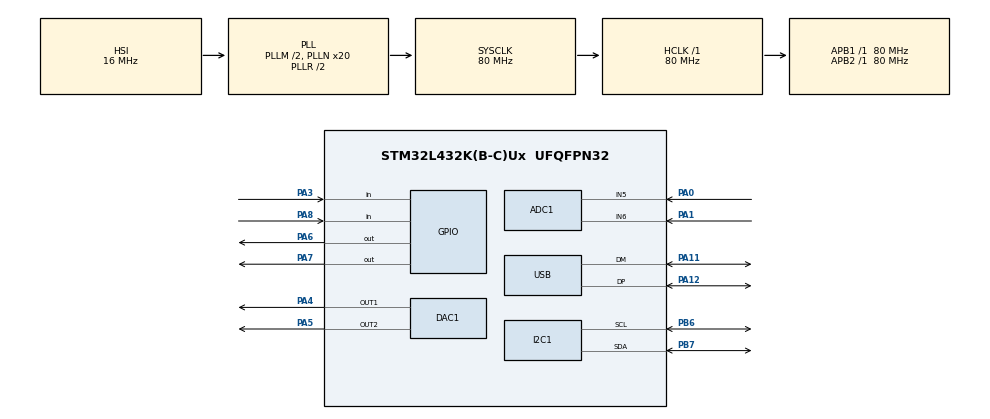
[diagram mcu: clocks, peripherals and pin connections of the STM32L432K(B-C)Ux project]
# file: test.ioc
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ADC1.AutoInjectedConv=DISABLE
ADC1.Channel-31\#ChannelRegularConversion=ADC_CHANNEL_5
ADC1.DMAContinuousRequests=ENABLE
ADC1.ExternalTrigConv=ADC_EXTERNALTRIG_T2_TRGO
ADC1.InjectedDiscontinuousConvMode=DISABLE
ADC1.NbrOfConversionFlag=1
ADC1.OffsetNumber-31\#ChannelRegularConversion=ADC_OFFSET_NONE
ADC1.Rank-31\#ChannelRegularConversion=1
ADC1.SamplingTime-31\#ChannelRegularConversion=ADC_SAMPLETIME_2CYCLES_5
ADC1.SingleDiff-31\#ChannelRegularConversion=ADC_DIFFERENTIAL_ENDED
ADC1.master=1
DAC1.DAC_Channel-DAC_OUT1=DAC_CHANNEL_1
DAC1.DAC_Channel-DAC_OUT2=DAC_CHANNEL_2
DAC1.DAC_Trigger-DAC_OUT2=DAC_TRIGGER_T6_TRGO
DAC1.WaveGeneration-DAC_OUT1=DISABLE
DAC1.WaveGeneration-DAC_OUT2=DISABLE
Dma.ADC1.1.Direction=DMA_PERIPH_TO_MEMORY
Dma.ADC1.1.Instance=DMA1_Channel1
Dma.ADC1.1.MemDataAlignment=DMA_MDATAALIGN_HALFWORD
Dma.ADC1.1.MemInc=DMA_MINC_ENABLE
Dma.ADC1.1.Mode=DMA_CIRCULAR
Dma.ADC1.1.PeriphDataAlignment=DMA_PDATAALIGN_HALFWORD
Dma.ADC1.1.PeriphInc=DMA_PINC_DISABLE
Dma.ADC1.1.Priority=DMA_PRIORITY_LOW
Dma.DAC_CH2.0.Direction=DMA_MEMORY_TO_PERIPH
Dma.DAC_CH2.0.Instance=DMA1_Channel4
Dma.DAC_CH2.0.MemDataAlignment=DMA_MDATAALIGN_HALFWORD
Dma.DAC_CH2.0.MemInc=DMA_MINC_ENABLE
Dma.DAC_CH2.0.Mode=DMA_CIRCULAR
Dma.DAC_CH2.0.PeriphDataAlignment=DMA_PDATAALIGN_HALFWORD
Dma.DAC_CH2.0.PeriphInc=DMA_PINC_DISABLE
Dma.DAC_CH2.0.Priority=DMA_PRIORITY_LOW
Dma.Request0=DAC_CH2
Dma.Request1=ADC1
I2C1.OwnAddress2Masks=I2C_OA2_NOMASK
Mcu.Family=STM32L4
Mcu.Name=STM32L432K(B-C)Ux
Mcu.Package=UFQFPN32
NVIC.DMA1_Channel1_IRQn=true\:0\:0\:false\:false\:true
NVIC.DMA1_Channel4_IRQn=true\:0\:0\:false\:false\:true
NVIC.PriorityGroup=NVIC_PRIORITYGROUP_4
NVIC.USB_IRQn=true\:0\:0\:false\:false\:true
PA0-CK_IN.Signal=ADCx_IN5
PA1.Signal=ADCx_IN6
PA11.Mode=Device
PA11.Signal=USB_DM
PA12.Mode=Device
PA12.Signal=USB_DP
PA13\ (JTMS-SWDIO).Signal=SYS_JTMS-SWDIO
PA14\ (JTCK-SWCLK).Signal=SYS_JTCK-SWCLK
PA3.GPIO_Mode=GPIO_MODE_INPUT
PA3.GPIO_PuPd=GPIO_NOPULL
PA3.Signal=GPIO_Input
PA4.GPIO_Mode=GPIO_MODE_ANALOG
PA4.GPIO_PuPd=GPIO_NOPULL
PA4.Signal=COMP_DAC11_group
PA5.GPIO_Mode=GPIO_MODE_ANALOG
PA5.GPIO_PuPd=GPIO_NOPULL
PA5.Signal=COMP_DAC12_group
PA6.GPIO_ModeDefaultOutputPP=GPIO_MODE_OUTPUT_PP
PA6.GPIO_PuPd=GPIO_NOPULL
PA6.GPIO_Speed=GPIO_SPEED_FREQ_LOW
PA6.PinState=GPIO_PIN_RESET
PA6.Signal=GPIO_Output
PA7.GPIO_ModeDefaultOutputPP=GPIO_MODE_OUTPUT_PP
PA7.GPIO_PuPd=GPIO_NOPULL
PA7.GPIO_Speed=GPIO_SPEED_FREQ_LOW
PA7.PinState=GPIO_PIN_RESET
PA7.Signal=GPIO_Output
PA8.GPIO_Mode=GPIO_MODE_INPUT
PA8.GPIO_PuPd=GPIO_NOPULL
PA8.Signal=GPIO_Input
PB6.GPIO_FM6=__NULL
PB6.GPIO_Mode=GPIO_MODE_AF_OD
PB6.GPIO_PuPdOD=GPIO_PULLUP
PB6.GPIO_Speed=GPIO_SPEED_FREQ_VERY_HIGH
PB6.Mode=I2C
PB6.Signal=I2C1_SCL
PB7.GPIO_FM7=__NULL
PB7.GPIO_Mode=GPIO_MODE_AF_OD
PB7.GPIO_PuPdOD=GPIO_PULLUP
PB7.GPIO_Speed=GPIO_SPEED_FREQ_VERY_HIGH
PB7.Mode=I2C
PB7.Signal=I2C1_SDA
RCC.ADCCLockSelection=RCC_ADCCLKSOURCE_SYSCLK
RCC.ADCFreq_Value=80000000
RCC.AHBCLKDivider=RCC_SYSCLK_DIV1
RCC.AHBFreq_Value=80000000
RCC.APB1Freq_Value=80000000
RCC.APB1TimFreq_Value=80000000
RCC.APB2Freq_Value=80000000
RCC.APB2TimFreq_Value=80000000
RCC.CK48CLockSelection=RCC_USBCLKSOURCE_HSI48
RCC.ClockTypeHCLK=RCC_CLOCKTYPE_HCLK
RCC.ClockTypePCLK1=RCC_CLOCKTYPE_PCLK1
RCC.ClockTypePCLK2=RCC_CLOCKTYPE_PCLK2
RCC.ClockTypeSysClk=RCC_CLOCKTYPE_SYSCLK
RCC.CortexFreq_Value=80000000
RCC.EnableCSSLSE=false
RCC.EnbaleCSS=false
RCC.HCLKFreq_Value=80000000
RCC.HSE_VALUE=8000000
RCC.HSI48_VALUE=48000000
RCC.HSI_VALUE=16000000
RCC.I2C1CLockSelection=RCC_I2C1CLKSOURCE_SYSCLK
RCC.LSE_VALUE=32768
RCC.MSIClockRange=RCC_MSIRANGE_9
RCC.MSI_VALUE=24000000
RCC.PLLM=2
RCC.PLLN=20
RCC.PLLR=RCC_PLLR_DIV2
RCC.PLLSAI1N=20
RCC.PLLSAI1Q=RCC_PLLQ_DIV2
RCC.PLLSAI1R=RCC_PLLR_DIV2
RCC.PLLSourceVirtual=RCC_PLLSOURCE_HSI
RCC.SYSCLKFreq_VALUE=80000000
RCC.SYSCLKSource=RCC_SYSCLKSOURCE_PLLCLK
RCC.USBFreq_Value=48000000
RCC.VCOOutputFreq_Value=160000000
SH.ADCx_IN5.0=ADC1_IN5,IN5-Differential
SH.ADCx_IN6.0=ADC1_IN6,IN5-Differential
SH.COMP_DAC11_group.0=DAC1_OUT1,DAC_OUT1
SH.COMP_DAC12_group.0=DAC1_OUT2,DAC_OUT2
TIM2.Period=800
TIM2.TIM_MasterOutputTrigger=TIM_TRGO_UPDATE
TIM6.Period=800
TIM6.TIM_MasterSlaveMode=TIM_MASTERSLAVEMODE_DISABLE
USB_DEVICE.CLASS_NAME_FS=CDC
USB_DEVICE.USBD_HandleTypeDef_FS=hUsbDevice_USB_FS
USB_DEVICE.VirtualMode=Cdc
USB_DEVICE.VirtualModeFS=Cdc_FS
VP_TIM2_VS_ClockSourceINT.Mode=Internal
VP_TIM6_VS_ClockSourceINT.Mode=Enable_Timer
VP_USB_DEVICE_VS_USB_DEVICE_CDC_FS.Mode=CDC_FS

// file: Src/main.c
/**
  ******************************************************************************
  * File Name          : main.c
  * Description        : Main program body
  ******************************************************************************
  *
  * Copyright (c) 2017 STMicroelectronics International N.V.
  * All rights reserved.
  *
  * Redistribution and use in source and binary forms, with or without
  * modification, are permitted, provided that the following conditions are met:
  *
  * 1. Redistribution of source code must retain the above copyright notice,
  *    this list of conditions and the following disclaimer.
  * 2. Redistributions in binary form must reproduce the above copyright notice,
  *    this list of conditions and the following disclaimer in the documentation
  *    and/or other materials provided with the distribution.
  * 3. Neither the name of STMicroelectronics nor the names of other
  *    contributors to this software may be used to endorse or promote products
  *    derived from this software without specific written permission.
  * 4. This software, including modifications and/or derivative works of this
  *    software, must execute solely and exclusively on microcontroller or
  *    microprocessor devices manufactured by or for STMicroelectronics.
  * 5. Redistribution and use of this software other than as permitted under
  *    this license is void and will automatically terminate your rights under
  *    this license.
  *
  * THIS SOFTWARE IS PROVIDED BY STMICROELECTRONICS AND CONTRIBUTORS "AS IS"
  * AND ANY EXPRESS, IMPLIED OR STATUTORY WARRANTIES, INCLUDING, BUT NOT
  * LIMITED TO, THE IMPLIED WARRANTIES OF MERCHANTABILITY, FITNESS FOR A
  * PARTICULAR PURPOSE AND NON-INFRINGEMENT OF THIRD PARTY INTELLECTUAL PROPERTY
  * RIGHTS ARE DISCLAIMED TO THE FULLEST EXTENT PERMITTED BY LAW. IN NO EVENT
  * SHALL STMICROELECTRONICS OR CONTRIBUTORS BE LIABLE FOR ANY DIRECT, INDIRECT,
  * INCIDENTAL, SPECIAL, EXEMPLARY, OR CONSEQUENTIAL DAMAGES (INCLUDING, BUT NOT
  * LIMITED TO, PROCUREMENT OF SUBSTITUTE GOODS OR SERVICES; LOSS OF USE, DATA,
  * OR PROFITS; OR BUSINESS INTERRUPTION) HOWEVER CAUSED AND ON ANY THEORY OF
  * LIABILITY, WHETHER IN CONTRACT, STRICT LIABILITY, OR TORT (INCLUDING
  * NEGLIGENCE OR OTHERWISE) ARISING IN ANY WAY OUT OF THE USE OF THIS SOFTWARE,
  * EVEN IF ADVISED OF THE POSSIBILITY OF SUCH DAMAGE.
  *
  ******************************************************************************
  */
#include "main.h"
#include "stm32l4xx_hal.h"
#include "usb_device.h"
#include "dac_values.h"
#include "stm32l4xx_it.h"

ADC_HandleTypeDef hadc1;
DMA_HandleTypeDef hdma_adc1;

DAC_HandleTypeDef hdac1;
DMA_HandleTypeDef hdma_dac_ch2;

I2C_HandleTypeDef hi2c1;

TIM_HandleTypeDef htim2;
TIM_HandleTypeDef htim6;

/* USER CODE BEGIN PV */
/* Private variables ---------------------------------------------------------*/

/* USER CODE END PV */

void SystemClock_Config(void);
void Error_Handler(void);
static void MX_GPIO_Init(void);
static void MX_DMA_Init(void);
static void MX_DAC1_Init(void);
static void MX_I2C1_Init(void);
static void MX_TIM2_Init(void);
static void MX_ADC1_Init(void);
static void MX_TIM6_Init(void);
volatile int x = 0;
volatile int y = 0;
volatile uint16_t dac_buffer[2048] = DAC_BUFF;
volatile int z = 0;
volatile int q = 0;
int counter = 0;

/* USER CODE BEGIN PFP */
/* Private function prototypes -----------------------------------------------*/

/* USER CODE END PFP */

int main(void)
{

  /* MCU Configuration----------------------------------------------------------*/

  /* Reset of all peripherals, Initializes the Flash interface and the Systick. */
  HAL_Init();

  /* Configure the system clock */
  SystemClock_Config();

  /* Initialize all configured peripherals */
  MX_GPIO_Init();
  MX_DMA_Init();
  MX_DAC1_Init();
  MX_I2C1_Init();
  MX_USB_DEVICE_Init();
  MX_TIM2_Init();
  MX_ADC1_Init();
  MX_TIM6_Init();

  /* Infinite loop */
  /* USER CODE BEGIN WHILE */

  //initialize DAC buffer
  //set up ADC and DAC DMA's
  HAL_TIM_Base_Start(&htim6);
  HAL_TIM_Base_Start(&htim2);

  HAL_GPIO_WritePin(GPIOB, GPIO_PIN_5, GPIO_PIN_SET);

  //wait for the timer to reach zero, to syncronize DMA's
  MX_USB_DEVICE_Init();
  while ((&htim6)->Instance->CNT != 0){
    //wait
  }
  HAL_DAC_Start_DMA(&hdac1, DAC_CHANNEL_2, dac_buffer, 2048, DAC_ALIGN_12B_R);
  HAL_ADC_Start_DMA(&hadc1, adc_buffer, 2048);

  //set AGC DAC
  HAL_DAC_Start(&hdac1, DAC_CHANNEL_1);
  HAL_DAC_SetValue(&hdac1, DAC_CHANNEL_1, DAC_ALIGN_12B_R, 300);
  HAL_DAC_Start(&hdac1, DAC_CHANNEL_1);

  while (1)
  {
  /* USER CODE END WHILE */
y = (&htim6)->Instance->CNT;
x++;

  }

}

/** System Clock Configuration
*/
void SystemClock_Config(void)
{

  RCC_OscInitTypeDef RCC_OscInitStruct;
  RCC_ClkInitTypeDef RCC_ClkInitStruct;
  RCC_PeriphCLKInitTypeDef PeriphClkInit;

    /**Initializes the CPU, AHB and APB busses clocks
    */
  RCC_OscInitStruct.OscillatorType = RCC_OSCILLATORTYPE_HSI48|RCC_OSCILLATORTYPE_HSI;
  RCC_OscInitStruct.HSIState = RCC_HSI_ON;
  RCC_OscInitStruct.HSI48State = RCC_HSI48_ON;
  RCC_OscInitStruct.HSICalibrationValue = 16;
  RCC_OscInitStruct.PLL.PLLState = RCC_PLL_ON;
  RCC_OscInitStruct.PLL.PLLSource = RCC_PLLSOURCE_HSI;
  RCC_OscInitStruct.PLL.PLLM = 2;
  RCC_OscInitStruct.PLL.PLLN = 20;
  RCC_OscInitStruct.PLL.PLLP = RCC_PLLP_DIV7;
  RCC_OscInitStruct.PLL.PLLQ = RCC_PLLQ_DIV2;
  RCC_OscInitStruct.PLL.PLLR = RCC_PLLR_DIV2;
  if (HAL_RCC_OscConfig(&RCC_OscInitStruct) != HAL_OK)
  {
    Error_Handler();
  }

    /**Initializes the CPU, AHB and APB busses clocks
    */
  RCC_ClkInitStruct.ClockType = RCC_CLOCKTYPE_HCLK|RCC_CLOCKTYPE_SYSCLK
                              |RCC_CLOCKTYPE_PCLK1|RCC_CLOCKTYPE_PCLK2;
  RCC_ClkInitStruct.SYSCLKSource = RCC_SYSCLKSOURCE_PLLCLK;
  RCC_ClkInitStruct.AHBCLKDivider = RCC_SYSCLK_DIV1;
  RCC_ClkInitStruct.APB1CLKDivider = RCC_HCLK_DIV1;
  RCC_ClkInitStruct.APB2CLKDivider = RCC_HCLK_DIV1;

  if (HAL_RCC_ClockConfig(&RCC_ClkInitStruct, FLASH_LATENCY_4) != HAL_OK)
  {
    Error_Handler();
  }

  PeriphClkInit.PeriphClockSelection = RCC_PERIPHCLK_I2C1|RCC_PERIPHCLK_USB
                              |RCC_PERIPHCLK_ADC;
  PeriphClkInit.I2c1ClockSelection = RCC_I2C1CLKSOURCE_SYSCLK;
  PeriphClkInit.AdcClockSelection = RCC_ADCCLKSOURCE_SYSCLK;
  PeriphClkInit.UsbClockSelection = RCC_USBCLKSOURCE_HSI48;
  if (HAL_RCCEx_PeriphCLKConfig(&PeriphClkInit) != HAL_OK)
  {
    Error_Handler();
  }

    /**Configure the main internal regulator output voltage
    */
  if (HAL_PWREx_ControlVoltageScaling(PWR_REGULATOR_VOLTAGE_SCALE1) != HAL_OK)
  {
    Error_Handler();
  }

    /**Configure the Systick interrupt time
    */
  HAL_SYSTICK_Config(HAL_RCC_GetHCLKFreq()/1000);

    /**Configure the Systick
    */
  HAL_SYSTICK_CLKSourceConfig(SYSTICK_CLKSOURCE_HCLK);

  /* SysTick_IRQn interrupt configuration */
  HAL_NVIC_SetPriority(SysTick_IRQn, 0, 0);
}

/* ADC1 init function */
static void MX_ADC1_Init(void)
{

  ADC_ChannelConfTypeDef sConfig;

    /**Common config
    */
  hadc1.Instance = ADC1;
  hadc1.Init.ClockPrescaler = ADC_CLOCK_ASYNC_DIV1;
  hadc1.Init.Resolution = ADC_RESOLUTION_12B;
  hadc1.Init.DataAlign = ADC_DATAALIGN_RIGHT;
  hadc1.Init.ScanConvMode = ADC_SCAN_DISABLE;
  hadc1.Init.EOCSelection = ADC_EOC_SINGLE_CONV;
  hadc1.Init.LowPowerAutoWait = DISABLE;
  hadc1.Init.ContinuousConvMode = DISABLE;
  hadc1.Init.NbrOfConversion = 1;
  hadc1.Init.DiscontinuousConvMode = DISABLE;
  hadc1.Init.NbrOfDiscConversion = 1;
  hadc1.Init.ExternalTrigConv = ADC_EXTERNALTRIG_T6_TRGO;
  hadc1.Init.ExternalTrigConvEdge = ADC_EXTERNALTRIGCONVEDGE_RISING;
  hadc1.Init.DMAContinuousRequests = ENABLE;
  hadc1.Init.Overrun = ADC_OVR_DATA_PRESERVED;
  hadc1.Init.OversamplingMode = DISABLE;
  if (HAL_ADC_Init(&hadc1) != HAL_OK)
  {
    Error_Handler();
  }

    /**Configure Regular Channel
    */
  sConfig.Channel = ADC_CHANNEL_5;
  sConfig.Rank = 1;
  sConfig.SamplingTime = ADC_SAMPLETIME_24CYCLES_5;
  sConfig.SingleDiff = ADC_DIFFERENTIAL_ENDED;
  sConfig.OffsetNumber = ADC_OFFSET_NONE;
  sConfig.Offset = 0;
  if (HAL_ADC_ConfigChannel(&hadc1, &sConfig) != HAL_OK)
  {
    Error_Handler();
  }

}

/* DAC1 init function */
static void MX_DAC1_Init(void)
{

  DAC_ChannelConfTypeDef sConfig;

    /**DAC Initialization
    */
  hdac1.Instance = DAC1;
  if (HAL_DAC_Init(&hdac1) != HAL_OK)
  {
    Error_Handler();
  }

    /**DAC channel OUT1 config
    */
  sConfig.DAC_SampleAndHold = DAC_SAMPLEANDHOLD_DISABLE;
  sConfig.DAC_Trigger = DAC_TRIGGER_NONE;
  sConfig.DAC_OutputBuffer = DAC_OUTPUTBUFFER_ENABLE;
  sConfig.DAC_ConnectOnChipPeripheral = DAC_CHIPCONNECT_DISABLE;
  sConfig.DAC_UserTrimming = DAC_TRIMMING_FACTORY;
  if (HAL_DAC_ConfigChannel(&hdac1, &sConfig, DAC_CHANNEL_1) != HAL_OK)
  {
    Error_Handler();
  }

    /**DAC channel OUT2 config
    */
  sConfig.DAC_Trigger = DAC_TRIGGER_T6_TRGO;
  sConfig.DAC_ConnectOnChipPeripheral = DAC_CHIPCONNECT_DISABLE;
  if (HAL_DAC_ConfigChannel(&hdac1, &sConfig, DAC_CHANNEL_2) != HAL_OK)
  {
    Error_Handler();
  }

}

/* I2C1 init function */
static void MX_I2C1_Init(void)
{

  hi2c1.Instance = I2C1;
  hi2c1.Init.Timing = 0x10909CEC;
  hi2c1.Init.OwnAddress1 = 0;
  hi2c1.Init.AddressingMode = I2C_ADDRESSINGMODE_7BIT;
  hi2c1.Init.DualAddressMode = I2C_DUALADDRESS_DISABLE;
  hi2c1.Init.OwnAddress2 = 0;
  hi2c1.Init.OwnAddress2Masks = I2C_OA2_NOMASK;
  hi2c1.Init.GeneralCallMode = I2C_GENERALCALL_DISABLE;
  hi2c1.Init.NoStretchMode = I2C_NOSTRETCH_DISABLE;
  if (HAL_I2C_Init(&hi2c1) != HAL_OK)
  {
    Error_Handler();
  }

    /**Configure Analogue filter
    */
  if (HAL_I2CEx_ConfigAnalogFilter(&hi2c1, I2C_ANALOGFILTER_ENABLE) != HAL_OK)
  {
    Error_Handler();
  }

    /**Configure Digital filter
    */
  if (HAL_I2CEx_ConfigDigitalFilter(&hi2c1, 0) != HAL_OK)
  {
    Error_Handler();
  }

}

/* TIM2 init function */
static void MX_TIM2_Init(void)
{

  TIM_ClockConfigTypeDef sClockSourceConfig;
  TIM_MasterConfigTypeDef sMasterConfig;

  htim2.Instance = TIM2;
  htim2.Init.Prescaler = 0;
  htim2.Init.CounterMode = TIM_COUNTERMODE_UP;
  htim2.Init.Period = 800;
  htim2.Init.ClockDivision = TIM_CLOCKDIVISION_DIV1;
  if (HAL_TIM_Base_Init(&htim2) != HAL_OK)
  {
    Error_Handler();
  }

  sClockSourceConfig.ClockSource = TIM_CLOCKSOURCE_INTERNAL;
  if (HAL_TIM_ConfigClockSource(&htim2, &sClockSourceConfig) != HAL_OK)
  {
    Error_Handler();
  }

  sMasterConfig.MasterOutputTrigger = TIM_TRGO_UPDATE;
  sMasterConfig.MasterSlaveMode = TIM_MASTERSLAVEMODE_DISABLE;
  if (HAL_TIMEx_MasterConfigSynchronization(&htim2, &sMasterConfig) != HAL_OK)
  {
    Error_Handler();
  }

}

/* TIM6 init function */
static void MX_TIM6_Init(void)
{

  TIM_MasterConfigTypeDef sMasterConfig;

  htim6.Instance = TIM6;
  htim6.Init.Prescaler = 0;
  htim6.Init.CounterMode = TIM_COUNTERMODE_UP;
  htim6.Init.Period = 400;
  if (HAL_TIM_Base_Init(&htim6) != HAL_OK)
  {
    Error_Handler();
  }

  sMasterConfig.MasterOutputTrigger = TIM_TRGO_UPDATE;
  sMasterConfig.MasterSlaveMode = TIM_MASTERSLAVEMODE_DISABLE;
  if (HAL_TIMEx_MasterConfigSynchronization(&htim6, &sMasterConfig) != HAL_OK)
  {
    Error_Handler();
  }

}

static void MX_DMA_Init(void)
{
  /* DMA controller clock enable */
  __HAL_RCC_DMA1_CLK_ENABLE();

  /* DMA interrupt init */
  /* DMA1_Channel1_IRQn interrupt configuration */
  HAL_NVIC_SetPriority(DMA1_Channel1_IRQn, 0, 0);
  HAL_NVIC_EnableIRQ(DMA1_Channel1_IRQn);
  /* DMA1_Channel4_IRQn interrupt configuration */
  HAL_NVIC_SetPriority(DMA1_Channel4_IRQn, 0, 0);
  HAL_NVIC_EnableIRQ(DMA1_Channel4_IRQn);

}

/** Configure pins as
        * Analog
        * Input
        * Output
        * EVENT_OUT
        * EXTI
*/
static void MX_GPIO_Init(void)
{

  GPIO_InitTypeDef GPIO_InitStruct;

  /* GPIO Ports Clock Enable */
  __HAL_RCC_GPIOA_CLK_ENABLE();
  __HAL_RCC_GPIOB_CLK_ENABLE();

  /*Configure GPIO pin Output Level */
  HAL_GPIO_WritePin(GPIOA, GPIO_PIN_6|GPIO_PIN_7, GPIO_PIN_RESET);
  HAL_GPIO_WritePin(GPIOB, GPIO_PIN_5, GPIO_PIN_RESET);

  /*Configure GPIO pins : PA3 PA8 */
  GPIO_InitStruct.Pin = GPIO_PIN_3|GPIO_PIN_8;
  GPIO_InitStruct.Mode = GPIO_MODE_INPUT;
  GPIO_InitStruct.Pull = GPIO_NOPULL;
  HAL_GPIO_Init(GPIOA, &GPIO_InitStruct);

  /*Configure GPIO pins : PA6 PA7 */
  GPIO_InitStruct.Pin = GPIO_PIN_6|GPIO_PIN_7;
  GPIO_InitStruct.Mode = GPIO_MODE_OUTPUT_PP;
  GPIO_InitStruct.Pull = GPIO_NOPULL;
  GPIO_InitStruct.Speed = GPIO_SPEED_FREQ_LOW;
  HAL_GPIO_Init(GPIOA, &GPIO_InitStruct);

  GPIO_InitStruct.Pin = GPIO_PIN_5;
  GPIO_InitStruct.Mode = GPIO_MODE_OUTPUT_PP;
  GPIO_InitStruct.Pull = GPIO_NOPULL;
  GPIO_InitStruct.Speed = GPIO_SPEED_FREQ_LOW;
  HAL_GPIO_Init(GPIOB, &GPIO_InitStruct);

}

void Error_Handler(void)
{
  while(1)
  {
  }
}

/************************ (C) COPYRIGHT STMicroelectronics *****END OF FILE****/
